# STM32L073xx register map
File version: 1.0
Registers are 32-bit, read-write, reset 0x0 unless marked. A register's access mark holds for its fields unless they carry their own. Offsets are from the block's base; [hi:lo] are bit positions; {n}, {i} and the like mark numbered series.

## LCD
Base 0x40002400
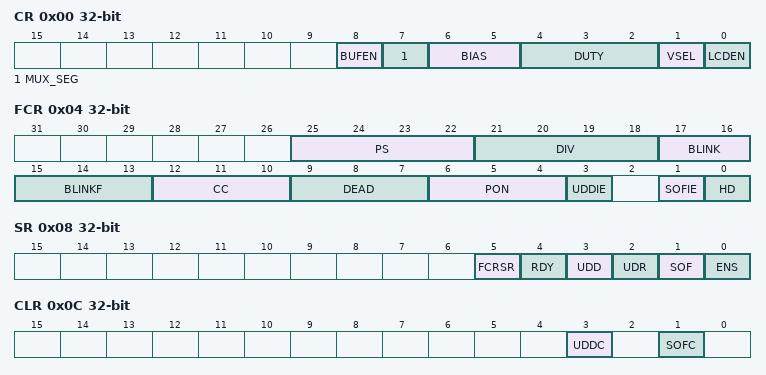
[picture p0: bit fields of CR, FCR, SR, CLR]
0x00 CR — LCD control register
  [8] BUFEN — Voltage output buffer enable Bit
  [7] MUX_SEG — Mux Segment Enable Bit
  [6:5] BIAS — BIAS[1:0] bits (Bias selector)
  [4:2] DUTY — DUTY[2:0] bits (Duty selector)
  [1] VSEL — Voltage source selector Bit
  [0] LCDEN — LCD Enable Bit
0x04 FCR — LCD frame control register
  [25:22] PS — PS[3:0] bits (Prescaler)
  [21:18] DIV — DIV[3:0] bits (Divider)
  [17:16] BLINK — BLINK[1:0] bits (Blink Enable)
  [15:13] BLINKF — BLINKF[2:0] bits (Blink Frequency)
  [12:10] CC — CC[2:0] bits (Contrast Control)
  [9:7] DEAD — DEAD[2:0] bits (DEAD Time)
  [6:4] PON — PON[2:0] bits (Pulse ON Duration)
  [3] UDDIE — Update Display Done Interrupt Enable Bit
  [1] SOFIE — Start of Frame Interrupt Enable Bit
  [0] HD — High Drive Enable Bit
0x08 SR — LCD status register
  [5] FCRSR — LCD FCR Register Synchronization Flag Bit
  [4] RDY — Ready Flag Bit
  [3] UDD — Update Display Done Flag Bit
  [2] UDR — Update Display Request Bit
  [1] SOF — Start Of Frame Flag Bit
  [0] ENS — LCD Enabled Bit
0x0C CLR — LCD clear register
  [3] UDDC — Update Display Done Flag Clear Bit
  [1] SOFC — Start Of Frame Flag Clear Bit
{0x14+4i} RAM{i} (i=0..15) — LCD display memory
  [31:0] SEGMENT_DATA — Segment Data Bits

## WWDG — Window WATCHDOG
Base 0x40002C00
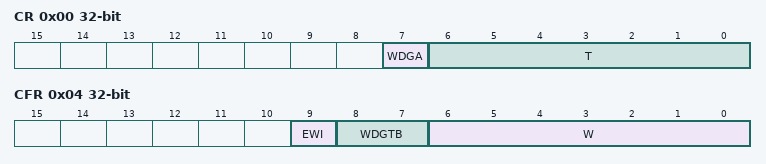
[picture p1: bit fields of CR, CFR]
0x00 CR — WWDG Control register
  [7] WDGA — Activation bit
  [6:0] T — T[6:0] bits (7-Bit counter (MSB to LSB))
0x04 CFR — WWDG Configuration register
  [9] EWI — Early Wakeup Interrupt
  [8:7] WDGTB — WDGTB[1:0] bits (Timer Base)
    0=PRESCALER_1 (WWDG counter clock = (PCLK1/4096)/1); 1=PRESCALER_2 (WWDG counter clock = (PCLK1/4096)/2); 2=PRESCALER_4 (WWDG counter clock = (PCLK1/4096)/4); 3=PRESCALER_8 (WWDG counter clock = (PCLK1/4096)/8)
  [6:0] W — W[6:0] bits (7-bit window value)
0x08 SR — WWDG Status register
  [0] EWIF — Early Wakeup Interrupt Flag

## IWDG — Independent WATCHDOG
Base 0x40003000
0x00 KR — IWDG Key register
  [15:0] KEY — Key value (write only, read 0000h)
0x04 PR — IWDG Prescaler register
  [2:0] PR — PR[2:0] (Prescaler divider)
0x08 RLR — IWDG Reload register
  [11:0] RL — Watchdog counter reload value
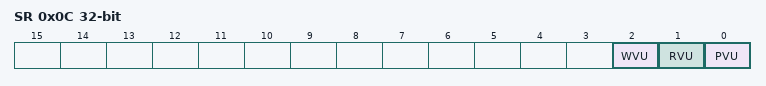
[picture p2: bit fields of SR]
0x0C SR — IWDG Status register
  [2] WVU — Watchdog counter window value update
  [1] RVU — Watchdog counter reload value update
  [0] PVU — Watchdog prescaler value update
0x10 WINR — IWDG Window register
  [11:0] WIN — Watchdog counter window value

## SPI2 — Serial Peripheral Interface
Base 0x40003800
Same registers: SPI1 0x40013000
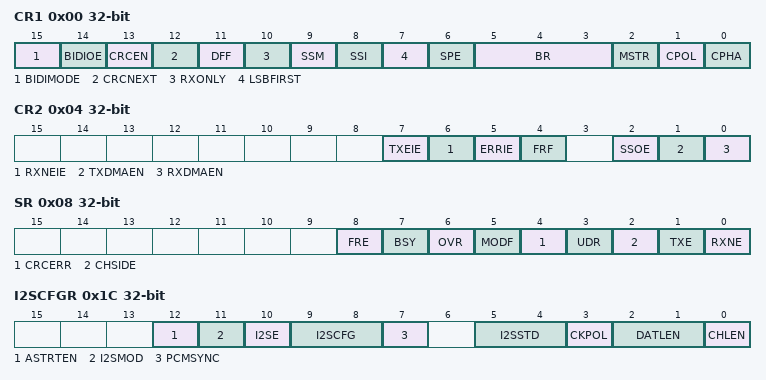
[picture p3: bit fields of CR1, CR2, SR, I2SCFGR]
0x00 CR1 — SPI Control register 1 (not used in I2S mode)
  [15] BIDIMODE — Bidirectional data mode enable
  [14] BIDIOE — Output enable in bidirectional mode
  [13] CRCEN — Hardware CRC calculation enable
  [12] CRCNEXT — Transmit CRC next
  [11] DFF — Data Frame Format
    0=DATAWIDTH_8BIT (Data length for SPI transfer: 8 bits); 1=DATAWIDTH_16BIT (Data length for SPI transfer: 16 bits)
  [10] RXONLY — Receive only
  [9] SSM — Software slave management
  [8] SSI — Internal slave select
  [7] LSBFIRST — Frame Format
    1=LSB_FIRST (Data is transmitted/received with the LSB first); 0=MSB_FIRST (Data is transmitted/received with the MSB first)
  [6] SPE — SPI Enable
  [5:3] BR — BR[2:0] bits (Baud Rate Control)
    0=DIV2 (BaudRate control equal to fPCLK/2); 1=DIV4 (BaudRate control equal to fPCLK/4); 2=DIV8 (BaudRate control equal to fPCLK/8); 3=DIV16 (BaudRate control equal to fPCLK/16); 4=DIV32 (BaudRate control equal to fPCLK/32); 5=DIV64 (BaudRate control equal to fPCLK/64); 6=DIV128 (BaudRate control equal to fPCLK/128); 7=DIV256 (BaudRate control equal to fPCLK/256)
  [2] MSTR — Master Selection
  [1] CPOL — Clock Polarity
    0=LOW (Clock to 0 when idle); 1=HIGH (Clock to 1 when idle)
  [0] CPHA — Clock Phase
    0=PHASE_1EDGE (First clock transition is the first data capture edge); 1=PHASE_2EDGE (Second clock transition is the first data capture edge)
0x04 CR2 — SPI Control register 2
  [7] TXEIE — Tx buffer Empty Interrupt Enable
  [6] RXNEIE — RX buffer Not Empty Interrupt Enable
  [5] ERRIE — Error Interrupt Enable
  [4] FRF — Frame Format Enable
    0=MOTOROLA (Motorola mode. Used as default value); 1=TI (TI mode)
  [2] SSOE — SS Output Enable
  [1] TXDMAEN — Tx Buffer DMA Enable
  [0] RXDMAEN — Rx Buffer DMA Enable
0x08 SR — SPI Status register
  [8] FRE — TI frame format error
  [7] BSY — Busy flag
  [6] OVR — Overrun flag
  [5] MODF — Mode fault
  [4] CRCERR — CRC Error flag
  [3] UDR — Underrun flag
  [2] CHSIDE — Channel side
  [1] TXE — Transmit buffer Empty
  [0] RXNE — Receive buffer Not Empty
0x0C DR — SPI data register
  [15:0] DR — Data Register
0x10 CRCPR — SPI CRC polynomial register (not used in I2S mode)
  [15:0] CRCPOLY — CRC polynomial register
0x14 RXCRCR — SPI Rx CRC register (not used in I2S mode)
  [15:0] RXCRC
0x18 TXCRCR — SPI Tx CRC register (not used in I2S mode)
  [15:0] TXCRC
0x1C I2SCFGR — SPI_I2S configuration register
  [12] ASTRTEN — Asynchronous start enable
  [11] I2SMOD — I2S mode selection
  [10] I2SE — I2S Enable
  [9:8] I2SCFG — I2SCFG[1:0] bits (I2S configuration mode)
    0=SLAVE_TX (Slave Tx configuration); 1=SLAVE_RX (Slave Rx configuration); 2=MASTER_TX (Master Tx configuration); 3=MASTER_RX (Master Rx configuration)
  [7] PCMSYNC — PCM frame synchronization
  [5:4] I2SSTD — I2SSTD[1:0] bits (I2S standard selection)
  [3] CKPOL — steady state clock polarity
    0=LOW (Clock steady state is low level); 1=HIGH (Clock steady state is high level)
  [2:1] DATLEN — DATLEN[1:0] bits (Data length to be transferred)
  [0] CHLEN — Channel length (number of bits per audio channel)
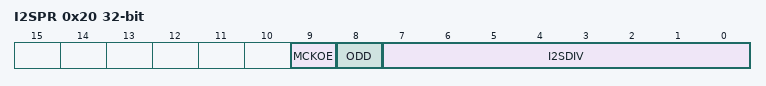
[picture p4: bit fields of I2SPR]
0x20 I2SPR — SPI_I2S prescaler register
  [9] MCKOE — Master Clock Output Enable
  [8] ODD — Odd factor for the prescaler
  [7:0] I2SDIV — I2S Linear prescaler
